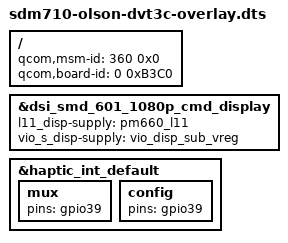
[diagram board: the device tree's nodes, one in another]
/* Copyright (c) 2018, The Linux Foundation. All rights reserved.
 *
 * This program is free software; you can redistribute it and/or modify
 * it under the terms of the GNU General Public License version 2 and
 * only version 2 as published by the Free Software Foundation.
 *
 * This program is distributed in the hope that it will be useful,
 * but WITHOUT ANY WARRANTY; without even the implied warranty of
 * MERCHANTABILITY or FITNESS FOR A PARTICULAR PURPOSE.  See the
 * GNU General Public License for more details.
 */

/dts-v1/;
/plugin/;

#include "sdm710-olson-common-overlay.dtsi"

/ {
	qcom,msm-id = <360 0x0>;
	qcom,board-id = <0 0xB3C0>;
};

/*
 * Olson HW rev DVT3C specific changes go here
 */

&dsi_smd_601_1080p_cmd_display {
	l11_disp-supply = <&pm660_l11>;
	vio_s_disp-supply = <&vio_disp_sub_vreg>;
};

&haptic_int_default {
	mux {
		pins = "gpio39";
	};

	config {
		pins = "gpio39";
	};
};
